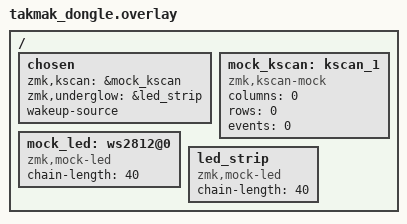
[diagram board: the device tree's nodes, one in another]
/*
 * Copyright (c) 2022 The ZMK Contributors
 *
 * SPDX-License-Identifier: MIT
 */

#include "takmak.dtsi"

/ {
    chosen {
        zmk,kscan = &mock_kscan;
        zmk,underglow = &led_strip;
        wakeup-source;
    };

    mock_kscan: kscan_1 {
        compatible = "zmk,kscan-mock";
        columns = <0>;
        rows = <0>;
        events = <0>;
    };

    mock_led: ws2812@0 {
        compatible = "zmk,mock-led";
        chain-length = <40>;
    };

    led_strip: led_strip {
        compatible = "zmk,mock-led";
        chain-length = <40>;
    };
};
